AUTOSAR XML (schema 4-0-3)
package /ComponentTypes
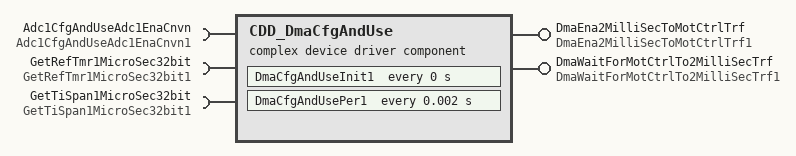
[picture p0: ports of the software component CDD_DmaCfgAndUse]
  complex device driver sw component type CDD_DmaCfgAndUse
    provide port DmaEna2MilliSecToMotCtrlTrf: server-com-spec{operation=Oper, queue-length=1}, provided-interface=DmaEna2MilliSecToMotCtrlTrf1
    provide port DmaWaitForMotCtrlTo2MilliSecTrf: server-com-spec{operation=Oper, queue-length=1}, provided-interface=DmaWaitForMotCtrlTo2MilliSecTrf1
    require port Adc1CfgAndUseAdc1EnaCnvn: required-interface=Adc1CfgAndUseAdc1EnaCnvn1
    require port GetRefTmr1MicroSec32bit: required-interface=GetRefTmr1MicroSec32bit1
    require port GetTiSpan1MicroSec32bit: required-interface=GetTiSpan1MicroSec32bit1
    behavior CDD_DmaCfgAndUse_InternalBehavior: data-type-mapping=Nexteer
      ar-typed-per-instance-memorys:
        7 x data, all with sw-calibration-access=READ-ONLY:
          d2MilliSecAdcActDmaTrfTi: type=uint32
          d2MilliSecAdcMaxDmaTrfTi: type=uint32
          DmaCfgAndUse2MilliSecAdcStrtTi: type=Cnt15
          MotAg0ReadPtrRst: type=uint32
          MotAg0TrsmStrt: type=Cnt15
          MotAg1ReadPtrRst: type=uint32
          MotAg1TrsmStrt: type=Cnt15
      timing event CDD_DmaCfgAndUse_InitEvent: start-on-event=DmaCfgAndUseInit1, period=0
      timing event TMT_DmaCfgAndUsePer1: start-on-event=DmaCfgAndUsePer1, period=0.002
      operation invoked event OIT_DmaEna2MilliSecToMotCtrlTrf_Oper_DmaEna2MilliSecToMotCtrlTrf_Oper: start-on-event=DmaEna2MilliSecToMotCtrlTrf_Oper, operation=DmaEna2MilliSecToMotCtrlTrf.Oper
      operation invoked event OIT_DmaWaitForMotCtrlTo2MilliSecTrf_Oper_DmaWaitForMotCtrlTo2MilliSecTrf_Oper: start-on-event=DmaWaitForMotCtrlTo2MilliSecTrf_Oper, operation=DmaWaitForMotCtrlTo2MilliSecTrf.Oper
      4 x runnable:
        DmaCfgAndUseInit1
        DmaCfgAndUsePer1
          sync call SC_Adc1CfgAndUseAdc1EnaCnvn1_Oper: operation=Adc1CfgAndUseAdc1EnaCnvn.Oper, timeout=0
          sync call SC_GetRefTmr1MicroSec32bit1_Oper: operation=GetRefTmr1MicroSec32bit.Oper, timeout=0
        DmaEna2MilliSecToMotCtrlTrf_Oper
        DmaWaitForMotCtrlTo2MilliSecTrf_Oper
          sync call SC_GetTiSpan1MicroSec32bit1_Oper: operation=GetTiSpan1MicroSec32bit.Oper, timeout=0
  swc implementation CDD_DmaCfgAndUse_Implementation: behavior=CDD_DmaCfgAndUse_InternalBehavior
    code-descriptors:
      code Default: artifact-descriptors=autosar-engineering-object={short-label=Default, category=SWSRC}
